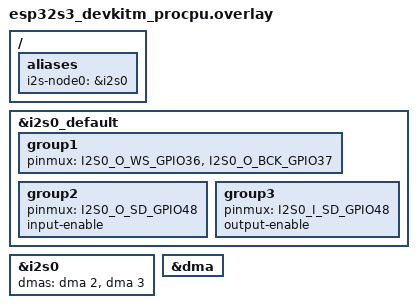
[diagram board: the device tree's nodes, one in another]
/*
 * Copyright (c) 2025 Espressif Systems (Shanghai) Co., Ltd.
 *
 * SPDX-License-Identifier: Apache-2.0
 */

/* i2s-node0 is the transmitter/receiver */

/ {
	aliases {
		i2s-node0 = &i2s0;
	};
};

&i2s0_default {
	group1 {
		pinmux = <I2S0_O_WS_GPIO36>,
			 <I2S0_O_BCK_GPIO37>;
	};

	group2 {
		pinmux =  <I2S0_O_SD_GPIO48>;
		input-enable;
	};

	group3 {
		pinmux = <I2S0_I_SD_GPIO48>;
		output-enable;
	};
};

&i2s0 {
	status = "okay";

	dmas = <&dma 2>, <&dma 3>;
	dma-names = "rx", "tx";
};

&dma {
	status = "okay";
};
